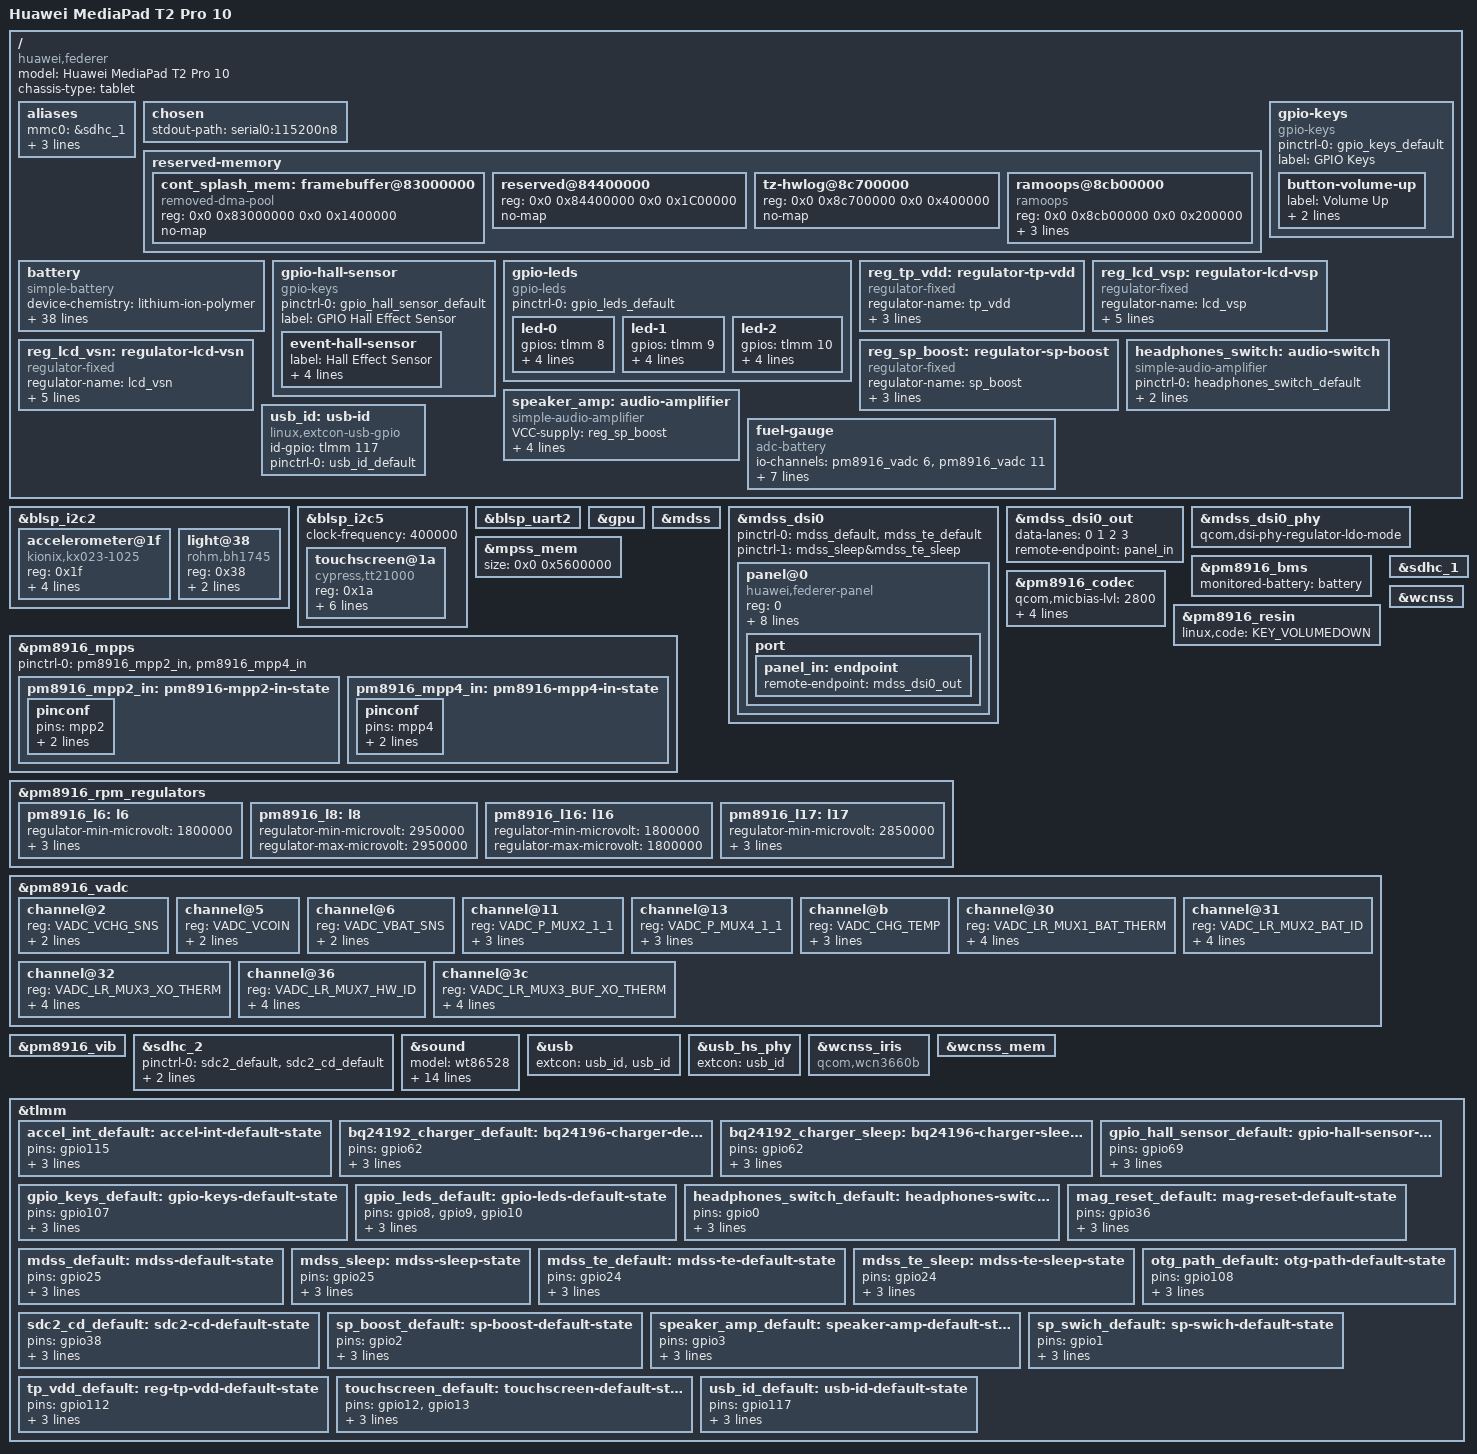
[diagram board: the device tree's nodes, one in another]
// SPDX-License-Identifier: GPL-2.0-only

/dts-v1/;

#include "msm8939-pm8916.dtsi"
#include "msm8916-modem.dtsi"

#include <dt-bindings/gpio/gpio.h>
#include <dt-bindings/input/input.h>
#include <dt-bindings/interrupt-controller/irq.h>
#include <dt-bindings/leds/common.h>
#include <dt-bindings/pinctrl/qcom,pmic-gpio.h>
#include <dt-bindings/pinctrl/qcom,pmic-mpp.h>

/ {
	model = "Huawei MediaPad T2 Pro 10";
	compatible = "huawei,federer", "qcom,msm8939";
	chassis-type = "tablet";

	aliases {
		mmc0 = &sdhc_1; /* eMMC */
		mmc1 = &sdhc_2; /* SD card */
		serial0 = &blsp_uart2;
		i2c0 = &blsp_i2c2;
	};

	chosen {
		stdout-path = "serial0:115200n8";
	};

	reserved-memory {
		cont_splash_mem: framebuffer@83000000 {
			compatible = "removed-dma-pool";
			reg = <0x0 0x83000000 0x0 0x1400000>;
			no-map;
		};

		reserved@84400000 {
			reg = <0x0 0x84400000 0x0 0x1C00000>;
			no-map;
		};

		tz-hwlog@8c700000 {
			reg = <0x0 0x8c700000 0x0 0x400000>;
			no-map;
		};

		ramoops@8cb00000 {
			compatible = "ramoops";
			reg = <0x0 0x8cb00000 0x0 0x200000>;

			record-size = <0x10000>;
			console-size = <0x100000>;
			ftrace-size = <0>;
		};
	};

	battery: battery {
		compatible = "simple-battery";
		device-chemistry = "lithium-ion-polymer";

		voltage-min-design-microvolt = <3350000>;
		voltage-max-design-microvolt = <4350000>;
		energy-full-design-microwatt-hours = <24700000>;
		charge-full-design-microamp-hours = <6500000>;

		precharge-current-microamp = <1300000>;
		charge-term-current-microamp = <260000>; //4%
		factory-internal-resistance-micro-ohms = <118000>;
		//operating-range-celsius = <0 52>;
		//alert-celsius = <10 42>;

		ocv-capacity-celsius = <(-25) 0 25>;
		/* table for -20 degree Celsius  data from HB26A510EBC_GY_SWD-4v35-6500mah.dtsi*/
		ocv-capacity-table-0 =  <4316000 100>,  <4200000 95>,  <4124000 90>,
			<4025000 85>,  <3964000 80>,  <3918000 75>,  <3883000 70>,
 			<3857000 65>,  <3836000 60>,  <3817000 55>,  <3800000 50>,
			 <3785000 45>,  <3770000 40>,  <3754000 35>,  <3737000 30>,
			 <3717000 25>,  <3694000 20>,  <3669000 16>,  <3645000 13>,
			 <3628000 11>,  <3616000 10>,  <3604000 9>,  <3586000 8>,
			 <3568000 7>,  <3544000 6>,  <3516000 5>,  <3478000 4>,
			 <3428000 3>,  <3360000 2>,  <3250000 1>,  <3000000 0>;
		/* table for 0 degree Celsius */
		ocv-capacity-table-1 =  <4315000 100>, <4250000 95>, <4190000 90>,
			<4136000 85>, <4085000 80>, <4032000 75>, <3957000 70>,
			<3918000 65>, <3885000 60>, <3854000 55>, <3828000 50>,
			<3806000 45>, <3790000 40>, <3777000 35>, <3765000 30>,
			<3751000 25>, <3732000 20>, <3712000 16>, <3698000 13>,
			<3690000 11>, <3686000 10>, <3680000 9>, <3674000 8>,
			<3664000 7>, <3648000 6>, <3623000 5>, <3584000 4>,
			<3530000 3>, <3449000 2>, <3316000 1>, <3000000 0>;
		/* table for 25 degree Celsius */
		ocv-capacity-table-2 = <4315000 100>, <4260000 95>, <4204000 90>,
			<4150000 85>, <4098000 80>, <4054000 75>, <3988000 70>,
			<3953000 65>, <3910000 60>, <3868000 55>, <3838000 50>,
			<3816000 45>, <3798000 40>, <3782000 35>, <3769000 30>,
			<3754000 25>, <3736000 20>, <3716000 16>, <3696000 13>,
			<3688000 11>, <3686000 10>, <3684000 9>, <3682000 8>,
			<3678000 7>, <3668000 6>, <3644000 5>, <3600000 4>,
			<3540000 3>, <3458000 2>, <3325000 1>, <3000000 0>;
	};

	gpio-hall-sensor {
		compatible = "gpio-keys";

		pinctrl-0 = <&gpio_hall_sensor_default>;
		pinctrl-names = "default";

		label = "GPIO Hall Effect Sensor";

		event-hall-sensor {
			label = "Hall Effect Sensor";
			gpios = <&tlmm 69 GPIO_ACTIVE_LOW>;
			linux,input-type = <EV_SW>;
			linux,code = <SW_LID>;
			linux,can-disable;
		};
	};

	gpio-keys {
		compatible = "gpio-keys";

		pinctrl-0 = <&gpio_keys_default>;
		pinctrl-names = "default";

		label = "GPIO Keys";

		button-volume-up {
			label = "Volume Up";
			gpios = <&tlmm 107 GPIO_ACTIVE_LOW>;
			linux,code = <KEY_VOLUMEUP>;
		};
	};

	gpio-leds {
		compatible = "gpio-leds";

		pinctrl-0 = <&gpio_leds_default>;
		pinctrl-names = "default";

		led-0 {
			gpios = <&tlmm 8 GPIO_ACTIVE_HIGH>;
			color = <LED_COLOR_ID_RED>;
			default-state = "off";
			function = LED_FUNCTION_INDICATOR;
			retain-state-suspended;
		};

		led-1 {
			gpios = <&tlmm 9 GPIO_ACTIVE_HIGH>;
			color = <LED_COLOR_ID_GREEN>;
			default-state = "off";
			function = LED_FUNCTION_INDICATOR;
			retain-state-suspended;
		};

		led-2 {
			gpios = <&tlmm 10 GPIO_ACTIVE_HIGH>;
			color = <LED_COLOR_ID_BLUE>;
			default-state = "off";
			function = LED_FUNCTION_INDICATOR;
			retain-state-suspended;
		};
	};

	reg_tp_vdd: regulator-tp-vdd {
		compatible = "regulator-fixed";
		regulator-name = "tp_vdd";

		gpio = <&tlmm 112 GPIO_ACTIVE_HIGH>;
		enable-active-high;
		//startup-delay-us = <200000>; //delay 200
		pinctrl-names = "default";
		pinctrl-0 = <&tp_vdd_default>;
	};

	reg_lcd_vsp: regulator-lcd-vsp {
		compatible = "regulator-fixed";
		regulator-name = "lcd_vsp";
		regulator-min-microvolt = <5400000>;
		regulator-max-microvolt = <5400000>;
		regulator-always-on;
		regulator-boot-on; // allows fb console to show up briefly at boot without always-on
		enable-active-high;

		/*gpio = <&tlmm 97 GPIO_ACTIVE_HIGH>;
		enable-active-high;
		startup-delay-us = <200000>; //delay 200
		pinctrl-names = "default";
		pinctrl-0 = <&lcd_vsp_default>;*/
	};

	reg_lcd_vsn: regulator-lcd-vsn {
		compatible = "regulator-fixed";
		regulator-name = "lcd_vsn";
		regulator-min-microvolt = <5400000>;
		regulator-max-microvolt = <5400000>;
		regulator-always-on;
		regulator-boot-on; // allows fb console to show up briefly at boot without always-on
		enable-active-high;

		/*gpio = <&tlmm 32 GPIO_ACTIVE_HIGH>;
		startup-delay-us = <200000>; //delay 200
		enable-active-high;
		pinctrl-names = "default";
		pinctrl-0 = <&lcd_vsn_default>;*/
	};

	reg_sp_boost: regulator-sp-boost {
		compatible = "regulator-fixed";
		regulator-name = "sp_boost";

		gpio = <&tlmm 2 GPIO_ACTIVE_HIGH>;
		enable-active-high;
		pinctrl-names = "default";
		pinctrl-0 = <&sp_boost_default>;
	};

	/*reg_sp_swich: regulator-sp-swich {
		compatible = "regulator-fixed";
		regulator-name = "sp_swich";
		vin-supply = <&reg_sp_boost>;

		gpio = <&tlmm 1 GPIO_ACTIVE_HIGH>;
		enable-active-high;
		//startup-delay-us = <200000>; //delay 200
		pinctrl-names = "default";
		pinctrl-0 = <&sp_swich_default>;
	};*/

	headphones_switch: audio-switch {
		compatible = "simple-audio-amplifier";

		pinctrl-names = "default";
		pinctrl-0 = <&headphones_switch_default>;

		enable-gpios = <&tlmm 0 GPIO_ACTIVE_HIGH>;
		sound-name-prefix = "Headphones Switch";
	};

	speaker_amp: audio-amplifier {
		compatible = "simple-audio-amplifier";
		VCC-supply = <&reg_sp_boost>;

		pinctrl-names = "default";
		pinctrl-0 = <&speaker_amp_default>;

		enable-gpios = <&tlmm 3 GPIO_ACTIVE_HIGH>; //enable
		startup-delay-us = <100000>; //delay 100ms
		sound-name-prefix = "Speaker Amp";
	};

	/* this is a power switch that connects otg power from bq24296 to the usb socket
	otg_path: otg-path {
		compatible = "regulator-fixed";
		regulator-name = "otg_path";
		vin-supply = <&usb_otg_vbus>;	// request otg booster of bq24296
		regulator-min-microvolt = <5000000>;
		regulator-max-microvolt = <5000000>;

		gpio =  <&tlmm 108 GPIO_ACTIVE_HIGH>;
		enable-active-high;
		pinctrl-names = "default";
		pinctrl-0 = <&otg_path_default>;
	}; */

	usb_id: usb-id {
		compatible = "linux,extcon-usb-gpio";
		id-gpio = <&tlmm 117 GPIO_ACTIVE_HIGH>;
		pinctrl-0 = <&usb_id_default>;
		pinctrl-names = "default";
	};
};

&blsp_i2c2 {
	status = "okay";

	accelerometer@1f {
		compatible = "kionix,kx023-1025";
		reg = <0x1f>;

		vdd-supply = <&pm8916_l17>;
		vddio-supply = <&pm8916_l6>;
		pinctrl-0 = <&accel_int_default>;
		pinctrl-names = "default";
		mount-matrix =  "-1", "0", "0",
				"0", "-1", "0",
				"0", "0", "1";
	};

	light@38 {
		compatible = "rohm,bh1745";
		reg = <0x38>;
		vdd-supply = <&pm8916_l17>;
		vio-supply = <&pm8916_l6>;
	};
};
/*
&blsp_i2c4 {
	status = "okay";

	charger: bq24296@6b {
		compatible = "ti,bq24296";
		reg = <0x6b>;
		interrupt-parent = <&tlmm>;
		interrupts = <62 IRQ_TYPE_LEVEL_HIGH>;
		pinctrl-names = "default", "sleep";
		pinctrl-0 = <&bq24192_charger_default>;
		pinctrl-1 = <&bq24192_charger_sleep>;
		omit-battery-class;
		usb_otg_vbus: usb-otg-vbus { };
	};
};*/

&blsp_i2c5 {
	status = "okay";
	clock-frequency = <400000>;

	touchscreen@1a {
		compatible = "cypress,tt21000";
		reg = <0x1a>;

		interrupt-parent = <&tlmm>;
		interrupts = <13 IRQ_TYPE_EDGE_FALLING>;

		reset-gpios = <&tlmm 12 GPIO_ACTIVE_LOW>;

		vdd-supply = <&reg_tp_vdd>;
		vddio-supply = <&pm8916_l16>;

		pinctrl-0 = <&touchscreen_default>;
		pinctrl-names = "default";
	};
};

&blsp_uart2 {
	status = "okay";
};

&gpu {
	status = "okay";
};

&mdss {
	status = "okay";
};

&mdss_dsi0 {
	pinctrl-0 = <&mdss_default &mdss_te_default>;
	pinctrl-1 = <&mdss_sleep&mdss_te_sleep>;
	pinctrl-names = "default", "sleep";
	status = "okay";

	panel@0 {
		compatible = "huawei,federer-panel";
		reg = <0>;

		vdd-supply = <&pm8916_l6>;
		vsp-supply = <&reg_lcd_vsp>;
		vsn-supply = <&reg_lcd_vsn>;
		power-gpios = <&tlmm 32 GPIO_ACTIVE_HIGH>;
		backlight-gpios = <&tlmm 97 GPIO_ACTIVE_HIGH>;
		blpwr-gpios = <&tlmm  109 GPIO_ACTIVE_HIGH>;

		reset-gpios = <&tlmm 25 GPIO_ACTIVE_LOW>;
		te-gpios = <&tlmm 24 GPIO_ACTIVE_HIGH>;

		port {
			panel_in: endpoint {
				remote-endpoint = <&mdss_dsi0_out>;
			};
		};
	};
};

&mdss_dsi0_out {
	data-lanes = <0 1 2 3>;
	remote-endpoint = <&panel_in>;
};

&mdss_dsi0_phy {
	qcom,dsi-phy-regulator-ldo-mode;
	status = "okay";
};

&mpss_mem {
	size = <0x0 0x5600000>;
};

&pm8916_bms {
	status = "okay";

	monitored-battery = <&battery>;
	//power-supplies = <&charger>;
};

&pm8916_codec {
	qcom,micbias-lvl = <2800>;
	qcom,mbhc-vthreshold-low = <75 150 237 450 500>;
	qcom,mbhc-vthreshold-high = <75 150 237 450 500>;
	qcom,micbias1-ext-cap;
	qcom,hphl-jack-type-normally-open;
	status = "okay";
};

&pm8916_mpps {
	pinctrl-names = "default";
	pinctrl-0 = <&pm8916_mpp2_in &pm8916_mpp4_in>;

	pm8916_mpp2_in: pm8916-mpp2-in-state {
		pinconf {
			pins = "mpp2";
			function = "analog"; //input
			qcom,amux-route = <1>; //PMIC_MPP_AMUX_ROUTE_CH6
		};
	};

	pm8916_mpp4_in: pm8916-mpp4-in-state {
		pinconf {
			pins = "mpp4";
			function = "analog"; //input
			qcom,amux-route = <3>; //PMIC_MPP_AMUX_ROUTE_CH8
		};
	};
};

&pm8916_resin {
	linux,code = <KEY_VOLUMEDOWN>;
	status = "okay";
};

&pm8916_rpm_regulators {
	pm8916_l6: l6 {
		regulator-min-microvolt = <1800000>;
		regulator-max-microvolt = <1800000>;
		regulator-always-on; 
		regulator-boot-on;
	};
	pm8916_l8: l8 {
		regulator-min-microvolt = <2950000>;
		regulator-max-microvolt = <2950000>;
	};
	pm8916_l16: l16 {
		regulator-min-microvolt = <1800000>;
		regulator-max-microvolt = <1800000>;
	};
	pm8916_l17: l17 {
		regulator-min-microvolt = <2850000>;
		regulator-max-microvolt = <2850000>;
		regulator-always-on; 
		regulator-boot-on;
	};
};

&pm8916_vadc {
	channel@2 {
		reg = <VADC_VCHG_SNS>;
		qcom,pre-scaling = <10 81>;
		label = "ireg_fb";
	};

	channel@5 {
		reg = <VADC_VCOIN>;
		qcom,pre-scaling = <1 3>;
		label = "vcoin";
	};

	channel@6 {
		reg = <VADC_VBAT_SNS>;
		qcom,pre-scaling = <1 3>;
		label = "vbat_sns";
	};

	channel@11 {
		reg = <VADC_P_MUX2_1_1>;
		qcom,pre-scaling = <1 1>;
		qcom,hw-settle-time = <200>;
		label = "pa_therm1";
	};

	channel@13 {
		reg = <VADC_P_MUX4_1_1>;
		qcom,pre-scaling = <1 1>;
		qcom,hw-settle-time = <200>;
		label = "case_therm";
	};

	channel@b {
		reg = <VADC_CHG_TEMP>;
		qcom,pre-scaling = <1 1>;
		qcom,hw-settle-time = <0>;
		label = "chg_temp";
	};

	channel@30 {
		reg = <VADC_LR_MUX1_BAT_THERM>;
		qcom,pre-scaling = <1 1>;
		qcom,ratiometric;
		qcom,hw-settle-time = <200>;
		label = "batt_therm";
	};

	channel@31 {
		reg = <VADC_LR_MUX2_BAT_ID>;
		qcom,pre-scaling = <1 1>;
		qcom,ratiometric;
		qcom,hw-settle-time = <2>;
		label = "batt_id";
	};

	channel@32 {
		reg = <VADC_LR_MUX3_XO_THERM>;
		qcom,pre-scaling = <1 1>;
		qcom,ratiometric;
		qcom,hw-settle-time = <200>;
		label = "xo_therm";
	};

	channel@36 {
		reg = <VADC_LR_MUX7_HW_ID>;
		qcom,pre-scaling = <1 1>;
		qcom,ratiometric;
		qcom,hw-settle-time = <200>;
		label = "pa_therm0";
	};

	channel@3c {
		reg = <VADC_LR_MUX3_BUF_XO_THERM>;
		qcom,pre-scaling = <1 1>;
		qcom,ratiometric;
		qcom,hw-settle-time = <200>;
		label = "xo_therm_buf";
	};
};

&pm8916_vib {
	status = "okay";
};

&sdhc_1 {
	status = "okay";
};

&sdhc_2 {
	pinctrl-0 = <&sdc2_default &sdc2_cd_default>;
	pinctrl-1 = <&sdc2_sleep &sdc2_cd_default>;
	pinctrl-names = "default", "sleep";

	cd-gpios = <&tlmm 38 GPIO_ACTIVE_LOW>;

	status = "okay";
};

&sound {
	status = "okay";

	model = "wt86528";
	widgets =
		"Speaker", "Speaker",
		"Headphone", "Headphones";
	pin-switches = "Speaker", "Headphones";
	audio-routing =
		"Speaker", "Speaker Amp OUTL",
		"Speaker", "Speaker Amp OUTR",
		"Speaker Amp INL", "HPH_L",
		"Speaker Amp INR", "HPH_R",
		"Headphones", "Headphones Switch OUTL",
		"Headphones", "Headphones Switch OUTR",
		"Headphones Switch INL", "HPH_L",
		"Headphones Switch INR", "HPH_R",
		"AMIC1", "MIC BIAS External1",
		"AMIC2", "MIC BIAS External2",
		"AMIC3", "MIC BIAS External1";
	aux-devs = <&speaker_amp>, <&headphones_switch>;
};

&usb {
	extcon = <&usb_id>, <&usb_id>;
	//extcon = <&charger>, <&usb_id>;
	//vbus-supply = <&usb_otg_vbus>;
	status = "okay";
};

&usb_hs_phy {
	extcon = <&usb_id>;
	//extcon = <&charger>;
};

&wcnss {
	status = "okay";
};

&wcnss_iris {
	compatible = "qcom,wcn3660b";
};

&wcnss_mem {
	status = "okay";
};

&tlmm {
	accel_int_default: accel-int-default-state {
		pins = "gpio115";
		function = "gpio";
		drive-strength = <2>;
		bias-disable;
	};

	bq24192_charger_default: bq24196-charger-default-state  {
		pins = "gpio62";
		function = "gpio";
		drive-strength = <2>;
		bias-pull-up;
	};

	bq24192_charger_sleep: bq24196-charger-sleep-state  {
		pins = "gpio62";
		function = "gpio";
		drive-strength = <2>;
		bias-pull-up;
	};

	gpio_hall_sensor_default: gpio-hall-sensor-default-state {
		pins = "gpio69";
		function = "gpio";
		drive-strength = <2>;
		bias-disable;
	};

	gpio_keys_default: gpio-keys-default-state {
		pins = "gpio107";
		function = "gpio";
		drive-strength = <2>;
		bias-pull-up;
	};

	gpio_leds_default: gpio-leds-default-state {
		pins = "gpio8", "gpio9", "gpio10";
		function = "gpio";
		drive-strength = <2>;
		bias-disable;
	};

	headphones_switch_default: headphones-switch-default-state {
		pins = "gpio0";
		function = "gpio";

		drive-strength = <2>;
		bias-disable;
	};

	mag_reset_default: mag-reset-default-state {
		pins = "gpio36";
		function = "gpio";
		drive-strength = <2>;
		bias-disable;
	};

	mdss_default: mdss-default-state {
		pins = "gpio25";
		function = "gpio";
		drive-strength = <8>;
		bias-disable;
	};

	mdss_sleep: mdss-sleep-state {
		pins = "gpio25";
		function = "gpio";
		drive-strength = <2>;
		bias-pull-down;
	};

	mdss_te_default: mdss-te-default-state {
		pins = "gpio24";
		//function = "gpio";
		function = "mdp_vsync";
		drive-strength = <2>;
		bias-pull-disable;
	};

	mdss_te_sleep: mdss-te-sleep-state {
		pins = "gpio24";
		//function = "gpio";
		function = "mdp_vsync";
		drive-strength = <2>;
		bias-pull-down;
	};

	otg_path_default: otg-path-default-state {
		pins = "gpio108";
		function = "gpio";
		drive-strength = <2>;
		bias-disable;
	};

	sdc2_cd_default: sdc2-cd-default-state {
		pins = "gpio38";
		function = "gpio";
		drive-strength = <2>;
		bias-disable;
	};

	sp_boost_default: sp-boost-default-state {
		pins = "gpio2";
		function = "gpio";

		drive-strength = <2>;
		bias-disable;
	};

	speaker_amp_default: speaker-amp-default-state {
		pins = "gpio3";
		function = "gpio";

		drive-strength = <2>;
		bias-disable;
	};

	sp_swich_default: sp-swich-default-state {
		pins = "gpio1";
		function = "gpio";
		drive-strength = <2>;
		bias-disable;
	};

	tp_vdd_default: reg-tp-vdd-default-state {
		pins = "gpio112";
		function = "gpio";
		drive-strength = <2>;
		bias-pull-up;
	};

	touchscreen_default: touchscreen-default-state {
		pins = "gpio12", "gpio13";
		function = "gpio";
		drive-strength = <2>;
		bias-disable;
	};

	usb_id_default: usb-id-default-state {
		pins = "gpio117";
		function = "gpio";
		drive-strength = <8>;
		bias-pull-up;
	};
};

/ {
/* was #include <dt-bindings/power/power.h> */

#define POWER_SUPPLY_TECHNOLOGY_NiMH 1
#define POWER_SUPPLY_TECHNOLOGY_LION 2
#define POWER_SUPPLY_TECHNOLOGY_LIPO 3
#define POWER_SUPPLY_TECHNOLOGY_LiFe 4
#define POWER_SUPPLY_TECHNOLOGY_NiCd 5
#define POWER_SUPPLY_TECHNOLOGY_LiMn 6

    fuel-gauge {
	    compatible = "adc-battery";
	    #address-cells = <1>;
	    #size-cells = <0>;

		io-channels = <&pm8916_vadc 6>, <&pm8916_vadc 11>;//, <&pm8916_vadc 30>;
		io-channel-names = "voltage", "current";//, "temperature";

	    //charged-gpios = <&msmgpio 62 GPIO_ACTIVE_HIGH>;
	    monitored-battery = <&battery>;
	  //  power-supplies = <&charger>;
	    technology = <POWER_SUPPLY_TECHNOLOGY_LIPO>;
	    battery-name = "huawei-battery";
	    charge_full_design = <6500000>;
	    charge_empty_design = <00>;
	    voltage_min_design = <3350000>;
	    voltage_max_design = <4350000>;
    };
};
